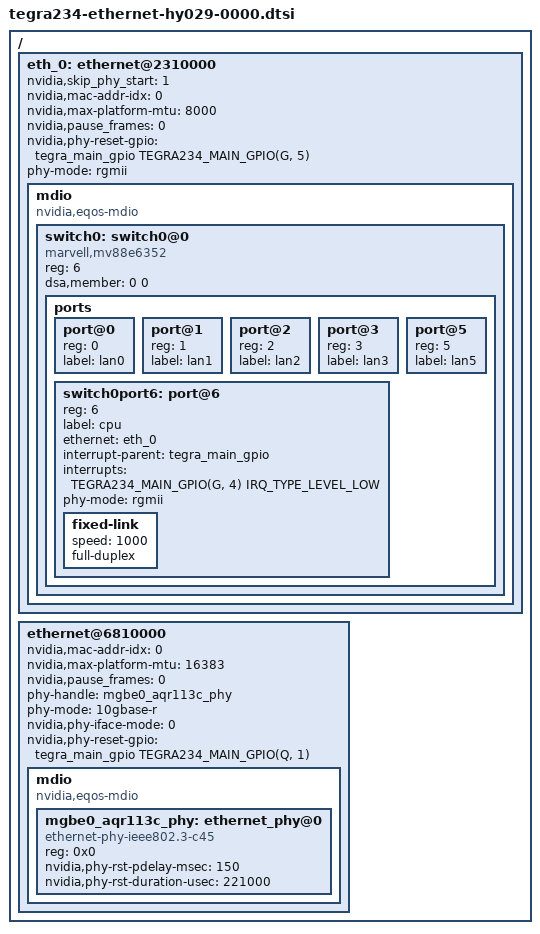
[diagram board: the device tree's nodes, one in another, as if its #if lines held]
/*
 * Copyright (c) 2021, NVIDIA CORPORATION.  All rights reserved.
 *
 * This program is free software; you can redistribute it and/or modify it
 * under the terms and conditions of the GNU General Public License,
 * version 2, as published by the Free Software Foundation.
 *
 * This program is distributed in the hope it will be useful, but WITHOUT
 * ANY WARRANTY; without even the implied warranty of MERCHANTABILITY or
 * FITNESS FOR A PARTICULAR PURPOSE.  See the GNU General Public License for
 * more details.
 *
 * You should have received a copy of the GNU General Public License
 * along with this program.  If not, see <http://www.gnu.org/licenses/>.
 */

#include <dt-bindings/gpio/tegra234-gpio.h>

/ {
#if defined(EQOS_RGMII_MV88E6352)
	/* EQOS RGMII I/F for mv88e6352
	 * MDC: E6
	 * MDIO: E7
	 */
	eth_0:ethernet@2310000 {
		status = "okay";
		nvidia,skip_phy_start = <1>;
		nvidia,mac-addr-idx = <0>;
		nvidia,max-platform-mtu = <8000>;
		/* 0=enable, 1=disable */
		nvidia,pause_frames = <0>;
		//xavier & orin: H5
		nvidia,phy-reset-gpio = <&tegra_main_gpio TEGRA234_MAIN_GPIO(G, 5) 0>;
		//phy-handle = <&switch0port6>;
		phy-mode = "rgmii";

		mdio {
			compatible = "nvidia,eqos-mdio";
			#address-cells = <1>;
			#size-cells = <0>;

			switch0: switch0@0 {
				compatible = "marvell,mv88e6352","marvell,mv88e6085";
				#address-cells = <1>;
				#size-cells = <0>;
				reg = <6>;

				dsa,member = <0 0>;

				ports {
					#address-cells = <1>;
					#size-cells = <0>;
					port@0 {
						reg = <0>;
						label = "lan0";
					};

					port@1 {
						reg = <1>;
						label = "lan1";
					};

					port@2 {
						reg = <2>;
						label = "lan2";
					};
					
					/* RJ45 */
					port@3 {
  						reg = <3>;
						label = "lan3";
					};
					
					/* 88Q2112 */
					port@5 {
						reg = <5>;
						label = "lan5";
					};

					switch0port6:port@6 {
						reg = <6>;
						label = "cpu";
						ethernet = <&eth_0>;
						//xavier & orin: J5
						//interrupts = <TEGRA194_MAIN_GPIO(G, 4) IRQ_TYPE_LEVEL_LOW>;
						interrupt-parent = <&tegra_main_gpio>;
						interrupts = <TEGRA234_MAIN_GPIO(G, 4) IRQ_TYPE_LEVEL_LOW>;
						phy-mode = "rgmii";
						fixed-link {
							speed = <1000>;
							full-duplex;
						};
					};
				};
			};

		};
	};
#endif

#if defined(XFI_AQR113C)
	/* MGBE - A */
	/* XFI0 I/F for aqr113c (p3737/hy029: MDC: H51; MDIO: K49; addr: ethernet@6810000) */
	ethernet@6810000 {
		status = "okay";
		nvidia,mac-addr-idx = <0>;
		nvidia,max-platform-mtu = <16383>;
		/* 0=enable, 1=disable */
		nvidia,pause_frames = <0>;
		phy-handle = <&mgbe0_aqr113c_phy>;
		phy-mode = "10gbase-r";
		/* 0:XFI 10G, 1:XFI 5G, 2:USXGMII 10G, 3:USXGMII 5G */
		nvidia,phy-iface-mode = <0>;
		/* p3737: D56 */
		/*nvidia,phy-reset-gpio = <&tegra_main_gpio TEGRA234_MAIN_GPIO(Y, 1) 0>;*/
		/* hy029: F56 */
		nvidia,phy-reset-gpio = <&tegra_main_gpio TEGRA234_MAIN_GPIO(Q, 1) 0>;
		mdio {
			compatible = "nvidia,eqos-mdio";
			#address-cells = <1>;
			#size-cells = <0>;

			mgbe0_aqr113c_phy: ethernet_phy@0 {
				compatible = "ethernet-phy-ieee802.3-c45";
				reg = <0x0>;
				nvidia,phy-rst-pdelay-msec = <150>; /* msec */
				nvidia,phy-rst-duration-usec = <221000>; /* usec */
			};
		};
	};
#endif
};
